# cmem7 register map
File version: 1.0
Registers are 32-bit, read-write, reset 0x0 unless marked. A register's access mark holds for its fields unless they carry their own. Offsets are from the block's base; [hi:lo] are bit positions; {n}, {i} and the like mark numbered series; 'fields as' and 'values as' point back to an identical list.

## ADC
Base 0x41006000
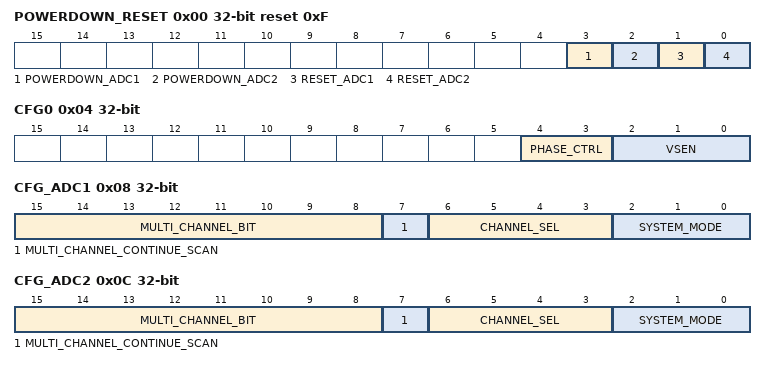
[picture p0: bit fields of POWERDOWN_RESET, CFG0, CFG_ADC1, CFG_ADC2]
0x00 POWERDOWN_RESET reset 0xF — power down and reset Register
  [3] POWERDOWN_ADC1 — ADC1, power down, active high
  [2] POWERDOWN_ADC2 — ADC2, power down, active high
  [1] RESET_ADC1 — ADC1, reset, active high
  [0] RESET_ADC2 — ADC2, reset, active high
0x04 CFG0 — config Register
  [4:3] PHASE_CTRL — ADC-1 and ADC-2 CLK Phase Control
    0=PHASE_0DEG_RISE_EDGE (ADC-1 and ADC-2 CLK are 0DEG Phase Difference(Rising Edge)); 1=PHASE_90DEG_AHEAD (ADC-1 90DEG ahead of ADC-2); 2=PHASE_90DEG_LAG (ADC-1 90DEG lag of ADC-2); 3=PHASE_0DEG_FALL_EDGE (ADC-1 and ADC-2 CLK are 0DEG Phase Difference(falling Edge))
  [2:0] VSEN — ADC-1 VSEN Selection
    1=VSEN_VDDCORE (Monitoring VDDCORE); 2=VSEN_VDDIO (Monitoring VDDIO); 4=VSEN_VDDIO2 (Monitoring VDDIO2)
0x08 CFG_ADC1 (reset mask 0x7FFF) — config ADC1 register
  [15:8] MULTI_CHANNEL_BIT — each bit represents each channel
  [7] MULTI_CHANNEL_CONTINUE_SCAN — If continue to scan multiply channel, else single scan
  [6:3] CHANNEL_SEL — channel selection
    0=ADCINPUT(+)=VIPP, ADCINPUT(-)=VIPN; 1=ADCINPUT(+)=VSENP, ADCINPUT(-)=VSENN; 2=ADCINPUT(+)=VTMP, ADCINPUT(-)=VTMPN; 3=ADCINPUT(+)=ADIOP[0], ADCINPUT(-)=ADION[0]; 4=ADCINPUT(+)=ADIOP[1], ADCINPUT(-)=ADION[1]; 5=ADCINPUT(+)=ADIOP[2], ADCINPUT(-)=ADION[2]]; 6=ADCINPUT(+)=ADIOP[3], ADCINPUT(-)=ADION[3]; 7=ADCINPUT(+)=ADIOP[4], ADCINPUT(-)=ADION[4]
  [2:0] SYSTEM_MODE — system mode selection
    0=SYSTEM_MODE_IDLE (idle); 1=SYSTEM_MODE_SINGLE_CONV (Single-Conversion); 2=SYSTEM_MODE_CONTINUOUS_CONV (Continuous Conversion); 3=SYSTEM_MODE_OFFSET_CALIBRATION (Calibration Mode, Offset Calibration(INPUT=0)); 4=SYSTEM_MODE_NEGTIVE_GAIN_CALIBRATION (Calibration Mode, Gain Calibration(INPUT=-FS)); 5=SYSTEM_MODE_POSITIVE_GAIN_CALIBRATION (Calibration Mode, Gain Calibration(INPUT=FS))
0x0C CFG_ADC2 (reset mask 0x7FFF) — config ADC1 register
  [15:8] MULTI_CHANNEL_BIT — each bit represents each channel
  [7] MULTI_CHANNEL_CONTINUE_SCAN — If continue to scan multiply channel, else single scan
  [6:3] CHANNEL_SEL — channel selection
    0=ADCINPUT(+)=VINP, ADCINPUT(-)=VINN; {v}=ADCINPUT(+)=ADIOP[{v+4}], ADCINPUT(-)=ADION[{v+4}] (v=1..7)
  [2:0] SYSTEM_MODE — system mode selection
    values as CFG_ADC1.SYSTEM_MODE
0x10 ADC1_FIFO_CLEAR — clear adc1 fifo data
  [0] CLEAR — clear fifo data, active high
0x14 ADC2_FIFO_CLEAR — clear adc2 fifo data
  [0] CLEAR — clear fifo data, active high
0x18 ALL_ADC_FIFO_CLEAR — clear adc1 and adc2 fifo data
  [0] CLEAR — clear fifo data, active high
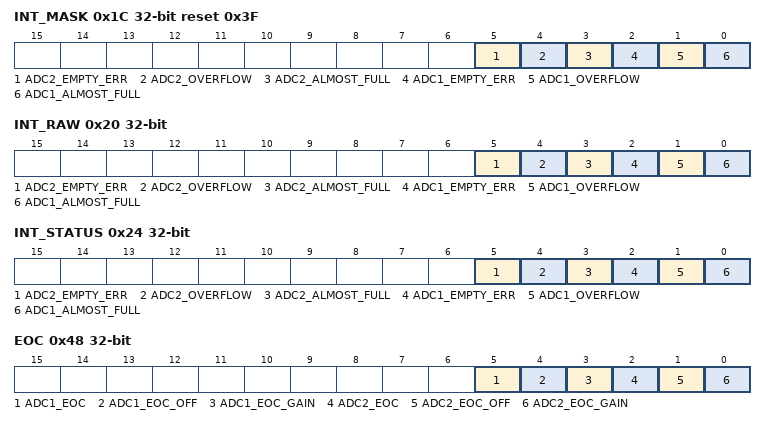
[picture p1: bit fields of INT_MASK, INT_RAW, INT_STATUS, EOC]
0x1C INT_MASK reset 0x3F — interrupt mask register
  [5] ADC2_EMPTY_ERR — ADC 2 read empty error
  [4] ADC2_OVERFLOW — ADC 2 is overflow
  [3] ADC2_ALMOST_FULL
  [2] ADC1_EMPTY_ERR — ADC 1 read empty error
  [1] ADC1_OVERFLOW — ADC 1 is overflow
  [0] ADC1_ALMOST_FULL
0x20 INT_RAW write-1-clears — interrupt raw register
  fields as INT_MASK
0x24 INT_STATUS write-1-clears — interrupt status register
  fields as INT_MASK
0x28 ADC1_OUT ro reset not defined — ADC-1 Output data (Signed-Magnitude Format)
0x2C ADC2_OUT ro reset not defined — ADC-2 Output data (Signed-Magnitude Format)
0x30 ADC1_OUT_OFFSET_CALIBRATION ro reset not defined — ADC-1 Output in offset calibration when Input=0, Ideally DAO[11:0]=000h
0x34 ADC2_OUT_OFFSET_CALIBRATION ro reset not defined — ADC-2 Output in offset calibration when Input=0, Ideally DAO[11:0]=000h
0x38 ADC1_OUT_NEGTIVE_GAIN_CALIBRATION ro reset not defined — ADC-1 Output in gain calibration when Input=-FS, Ideally DAO[11:0]=801h
0x3C ADC2_OUT_NEGTIVE_GAIN_CALIBRATION ro reset not defined — ADC-2 Output in gain calibration when Input=-FS, Ideally DAO[11:0]=801h
0x40 ADC1_OUT_POSITIVE_GAIN_CALIBRATION ro reset not defined — ADC-1 Output in gain calibration when Input=FS, Ideally DAO[11:0]=7FFh
0x44 ADC2_OUT_POSITIVE_GAIN_CALIBRATION ro reset not defined — ADC-2 Output in gain calibration when Input=FS, Ideally DAO[11:0]=7FFh
0x48 EOC ro reset not defined — Conversion End Indicator
  [5] ADC1_EOC — ADC1 EOC signal, conversion is done
  [4] ADC1_EOC_OFF — ADC1 EOC_OFF signal, conversion is done
  [3] ADC1_EOC_GAIN — ADC1 EOC_GAIN signal, conversion is done
  [2] ADC2_EOC — ADC2 EOC signal, conversion is done
  [1] ADC2_EOC_OFF — ADC2 EOC_OFF signal, conversion is done
  [0] ADC2_EOC_GAIN — ADC2 EOC_GAIN signal, conversion is done
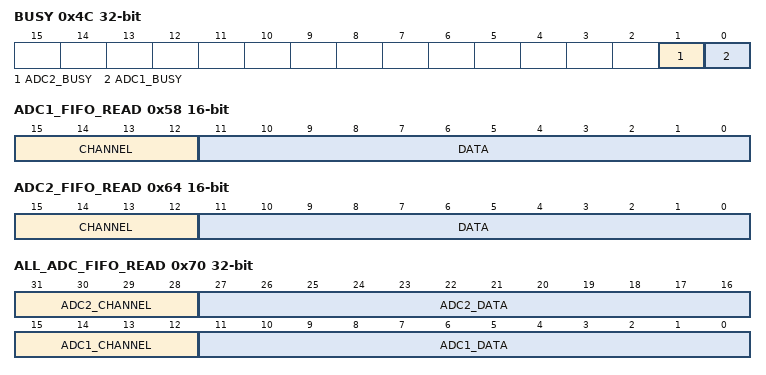
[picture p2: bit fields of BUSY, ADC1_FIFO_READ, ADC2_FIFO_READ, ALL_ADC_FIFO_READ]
0x4C BUSY ro reset not defined — ADC is busy
  [1] ADC2_BUSY — ADC2 is busy
  [0] ADC1_BUSY — ADC1 is busy
0x50 ADC1_START wo — ADC1 startup enable
  [0] EN — start
0x54 ADC1_STOP wo — ADC1 stop enable
  [0] EN — start
0x58 ADC1_FIFO_READ 16-bit wo reset not defined — ADC1 FIFO read data
  [15:12] CHANNEL — channel number
  [11:0] DATA
0x5C ADC2_START wo — ADC2 startup enable, only for single-conversion
  [0] EN — start
0x60 ADC2_STOP wo — ADC1 stop enable, only for single-conversion
  [0] EN — start
0x64 ADC2_FIFO_READ 16-bit wo reset not defined — ADC2 FIFO read data
  [15:12] CHANNEL — channel number
  [11:0] DATA
0x68 ALL_ADC_START wo — all ADCs start
  [0] EN — start
0x6C ALL_ADC_STOP wo — all ADCs stop
  [0] EN — start
0x70 ALL_ADC_FIFO_READ ro reset not defined — all ADCs FIFO read data
  [31:28] ADC2_CHANNEL — ADC2 channel number
  [27:16] ADC2_DATA
  [15:12] ADC1_CHANNEL — ADC1 channel number
  [11:0] ADC1_DATA
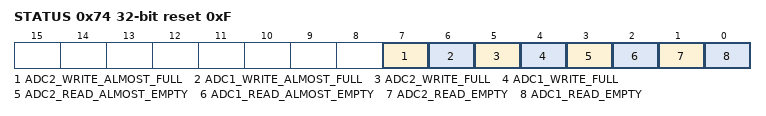
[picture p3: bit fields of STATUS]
0x74 STATUS ro reset 0xF
  [7] ADC2_WRITE_ALMOST_FULL, [6] ADC1_WRITE_ALMOST_FULL, [5] ADC2_WRITE_FULL, [4] ADC1_WRITE_FULL, [3] ADC2_READ_ALMOST_EMPTY, [2] ADC1_READ_ALMOST_EMPTY, [1] ADC2_READ_EMPTY, [0] ADC1_READ_EMPTY
